# GPTIMER2_L4Interconnect register map
Vendor: Texas Instruments
Peripheral module from a debugger description file (folder omap4460).
Registers are 32-bit, access per field, reset 0x0 unless marked. A register's access mark holds for its fields unless they carry their own. Offsets are as the file gives them; lines under a group give offsets from that group; [hi:lo] are bit positions; {n}, {i} and the like mark numbered series; 'fields as' and 'values as' point back to an identical list; <NAME> marks a mode.

## GPTIMER2_L4Interconnect
0x00 GPT_TIDR ro reset not defined — This read-only register contains the revision number of the module. A write to this register has no effect. This register is used by software to track features, bugs, and compatibility.
  [31:0] REVISION — IP Revision
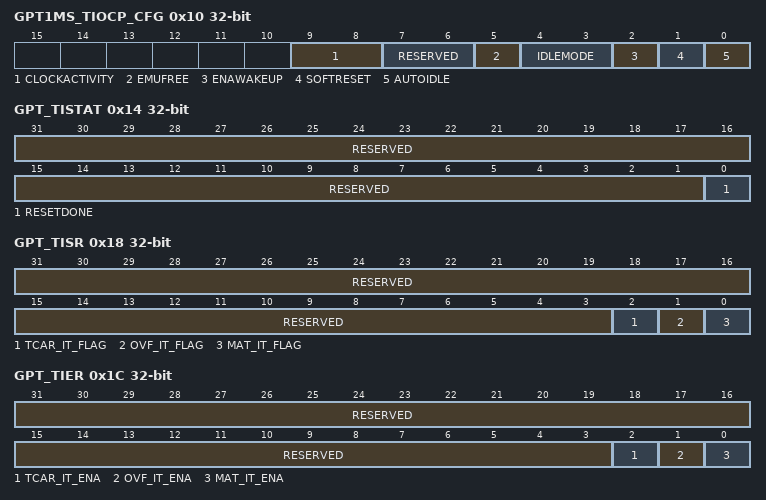
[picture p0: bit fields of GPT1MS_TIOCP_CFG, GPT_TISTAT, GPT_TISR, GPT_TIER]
0x10 GPT1MS_TIOCP_CFG — This register controls the various parameters of the OCP interface.
  [9:8] CLOCKACTIVITY rw
    0=Functional clock can be switched-off ; L4 clock can be switched-off; 1=Functional clock can be switched-off ; L4 clock is maintained during wake-up period; 2=Functional clock is maintained during wake-up period; L4 clock can be switched-off; 3=Functional clock is maintained during wake-up period; L4 clock is maintained during wake-up period
  [7:6] RESERVED ro — Write 0s for future compatibility. Reads return 0.
  [5] EMUFREE rw — Emulation mode
    0=Timer counter frozen in emulation; 1=Timer counter free-running in emulation
  [4:3] IDLEMODE rw — Power management, req/ack control
    0=Force-idle. An idle request is acknowledged unconditionally.; 1=No-idle. An idle request is never acknowledged.; 2=Smart-idle. Acknowledgment to an idle request is given based on the internal activity of the module.; 3=Reserved, do not use
  [2] ENAWAKEUP rw — Wake-up feature global control
    0=No wake-up line assertion in idle mode; 1=Wake-up line assertion enabled in smart-idle mode
  [1] SOFTRESET rw — Software reset. This bit is automatically reset by the hardware. During reads, it always returns 0.
    0=Normal mode; 1=The module is reset
  [0] AUTOIDLE rw — Internal L4 clock gating strategy
    0=L4 clock is free-running; 1=Automatic L4 clock gating strategy is applied, based on the L4 interface activity
0x14 GPT_TISTAT ro (reset mask 0xFFFFFFFE) — This register provides status information about the module, excluding interrupt status information.
  [31:1] RESERVED — Reads return 0.
  [0] RESETDONE — Internal reset monitoring
    0=RESETDONE_0_r (Internal module reset in ongoing.); 1=RESETDONE_1_r (Reset complete)
0x18 GPT_TISR — The timer status register is used to determine which of the timer events requested an interrupt.
  [31:3] RESERVED ro — Reads return 0.
  [2] TCAR_IT_FLAG rw — Indicates when an external pulse transition of the correct polarity is detected on external pin GPTi_EVENT_CAPTURE
    0=No capture interrupt request; 1=Capture interrupt request
  [1] OVF_IT_FLAG rw — TCRR overflow
    0=No overflow interrupt request; 1=Overflow interrupt pending
  [0] MAT_IT_FLAG rw — The compare result of TCRR and TMAR
    0=No compare interrupt request; 1=Compare interrupt pending
0x1C GPT_TIER — This register controls (enable/disable) the interrupt events.
  [31:3] RESERVED ro — Reads return 0.
  [2] TCAR_IT_ENA rw — Capture interrupt enable
    0=Disable capture interrupt; 1=Enable capture interrupt
  [1] OVF_IT_ENA rw — Overflow interrupt enable
    0=Disable overflow interrupt; 1=Enable overflow interrupt
  [0] MAT_IT_ENA rw — Match interrupt enable
    0=Disable match interrupt; 1=Enable match interrupt
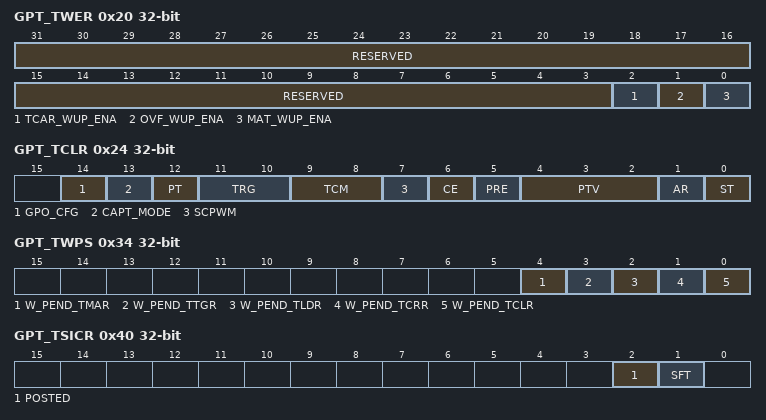
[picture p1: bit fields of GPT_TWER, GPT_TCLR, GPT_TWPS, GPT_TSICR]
0x20 GPT_TWER — This register controls (enable/disable) the wake-up feature on specific interrupt events.
  [31:3] RESERVED ro — Reads return 0
  [2] TCAR_WUP_ENA rw — Capture wake-up enable
    0=Disable capture wake-up; 1=Enable capture wake-up
  [1] OVF_WUP_ENA rw — Overflow wake-up enable
    0=Disable overflow wake-up; 1=Enable overflow wake-up
  [0] MAT_WUP_ENA rw — Match wake-up enable
    0=Disable match wake-up; 1=Enable match wake-up
0x24 GPT_TCLR — This register controls optional features specific to the timer functionality.
  [14] GPO_CFG rw — General-purpose output - this register directly drives the GPTi_PORGPOCFG output pin. For specific use of the GPO_CFG bit, see, .
    0=GPTi_PORGPOCFG drives 0; 1=GPTi_PORGPOCFG drives 1
  [13] CAPT_MODE rw — Capture mode select bit (first/second)
    0=Single capture: Capture the first enabled capture event in TCAR1; 1=Capture on second event: Capture the second enabled capture event in TCAR2
  [12] PT rw — Pulse or toggle mode on GPTi_PWM_out output pin
    0=Pulse modulation; 1=Toggle modulation
  [11:10] TRG rw — Trigger output mode on GPTi_PWM_out output pin
    0=No trigger; 1=Trigger on overflow; 2=Trigger on overflow and match
  [9:8] TCM rw — Transition capture mode on GPTi_EVENT_CAPTURE input pin (When the TCM field passed from (00) to any other combination, the TCAR_IT_FLAG and the edge detection logic are cleared.)
    0=No capture; 1=Capture on rising edges of GPTi_EVENT_CAPTURE pin; 2=Capture on falling edges of GPTi_EVENT_CAPTURE pin; 3=Capture on both edges of GPTi_EVENT_CAPTURE pin
  [7] SCPWM rw — Pulse width modulation output pin default settingThis bit must be set or clear while the timer is stopped or the trigger is off.
    0=Clear the GPTi_PWM_out output pin and select positive pulse for pulse mode; 1=Set the GPTi_PWM_out output pin and select negative pulse for pulse mode
  [6] CE rw — Compare enable
    0=Compare mode is disable; 1=Compare mode is enable
  [5] PRE rw — Prescaler enable
    0=The TIMER clock input pin clocks the counter; 1=The divided input pin clocks the counter
  [4:2] PTV rw — Prescale clock timer valueThe timer counter is prescaled with the value 2. Example: PTV = 3, counter increases value (if started) after 16 functional clock periods.
  [1] AR rw — Autoreload mode
    0=One shot timer; 1=Autoreload timer
  [0] ST rw — Start/stop timer control
    0=Stop timer: Only the counter is frozen. If one-shot mode selected (AR =0), this bit is automatically reset by internal logic when the counter is overflowed.; 1=Start timer
0x28 GPT_TCRR rw — This register holds the value of the internal counter.
  [31:0] TIMER_COUNTER — Value of TIMER counter
0x2C GPT_TLDR rw — This register holds the timer load value.
  [31:0] LOAD_VALUE — Timer counter value loaded on overflow in autoreload mode or onGPT_TTGR write access. LOAD_VALUE must be different than the timer overflow value (0xFFFF FFFF).
0x30 GPT_TTGR access not given reset 0xFFFFFFFF — The read value of this register is always 0xFFFF FFFF.
  [31:0] TTGR_VALUE — Writing to the TTGR register causes theGPT_TCRR to be loaded from GPT_TLDR and the prescaler counter to be cleared. Reload is done regardless of the AR field value of the GPT_TCLR register. (access RW Rreturns1s)
0x34 GPT_TWPS ro — This register contains the write posting bits for all writable functional registers.
  [4] W_PEND_TMAR — When equal to 1, a write is pending to theGPT_TMAR register.
  [3] W_PEND_TTGR — When equal to 1, a write is pending to theGPT_TTGR register.
  [2] W_PEND_TLDR — When equal to 1, a write is pending to theGPT_TLDR register.
  [1] W_PEND_TCRR — When equal to 1, a write is pending to theGPT_TCRR register.
  [0] W_PEND_TCLR — When equal to 1, a write is pending to theGPT_TCLR register.
0x38 GPT_TMAR rw — The compare logic consists of a 32-bit-wide, read/write data TMAR register and logic to compare counter.
  [31:0] COMPARE_VALUE — Value to be compared to the timer counter
0x3C GPT_TCAR1 ro — This register holds the first captured value of the counter register.
  [31:0] CAPTURE_VALUE1 — First timer counter value captured on an external event trigger
0x40 GPT_TSICR (reset mask 0xFFFFFFFB) — Timer synchronous interface control register
  [2] POSTED rw — Posted mode selection
    0=Posted mode inactive: Delay the command accept output signal; 1=Posted mode active
  [1] SFT rw — This bit resets all the functional part of the module.
    0=Software reset is disabled; 1=Software reset is enabled
0x44 GPT_TCAR2 ro — This register holds the second captured value of the counter register.
  [31:0] CAPTURE_VALUE2 — Second timer counter value captured on an external event trigger
0x48 GPT_TPIR rw — This register is used for 1-ms tick generation. The TPIR register holds the value of the positive increment. The value of this register is added to the value of TCVR to determine whether next value loaded in TCRR is the subperiod value or the overperiod value.
  [31:0] POSITIVE_INC_VALUE — Value of the positive increment
0x4C GPT_TNIR rw — This register is used for 1-ms tick generation. The TNIR register holds the value of the negative increment. The value of this register is added to the value of the TCVR to determine whether next value loaded in TCRR is the subperiod value or the overperiod value.
  [31:0] NEGATIVE_INV_VALUE — Value of the negative increment
0x50 GPT_TCVR rw — This register is used for 1-ms tick generation. The TCVR register determines whether next value loaded in TCRR is the subperiod value or the overperiod value.
  [31:0] COUNTER_VALUE — Value of CVR counter
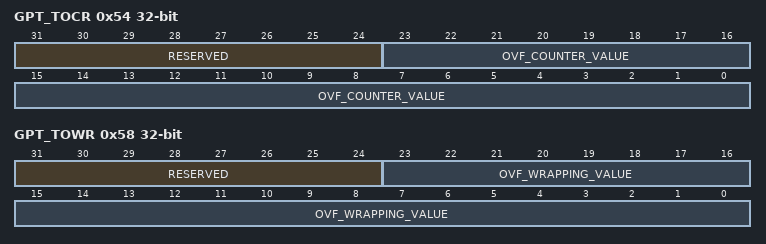
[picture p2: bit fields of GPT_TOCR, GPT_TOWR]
0x54 GPT_TOCR — This register is used to mask the tick interrupt for a selected number of ticks.
  [31:24] RESERVED ro — Reads return 0.
  [23:0] OVF_COUNTER_VALUE rw — Number of overflow events
0x58 GPT_TOWR — This register holds the number of masked overflow interrupts.
  [31:24] RESERVED ro — Reads return 0.
  [23:0] OVF_WRAPPING_VALUE rw — Number of masked interrupts
